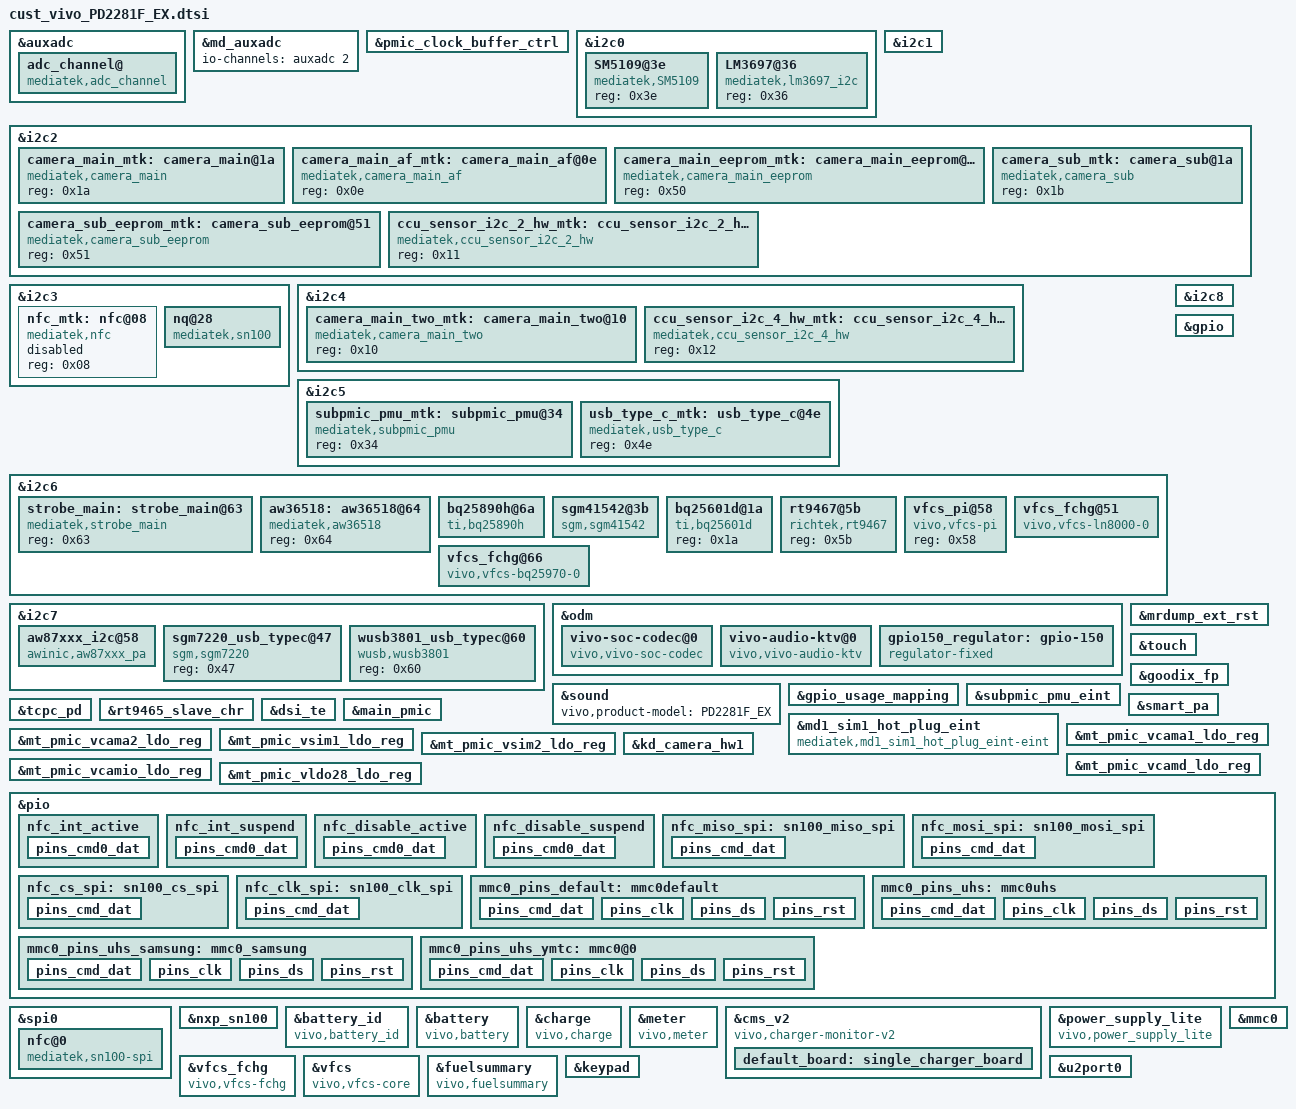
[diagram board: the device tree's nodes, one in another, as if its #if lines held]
/*
 * Generated by MTK SP DrvGen Version: 3.5.160809 for MT6768.
 * 2022-04-25 19:38:39
 * Do Not Modify The File.
 * Copyright Mediatek Inc. (c) 2016.
*/

/*************************
 * ADC DTSI File
*************************/

&auxadc {
	adc_channel@ {
		compatible = "mediatek,adc_channel";
		mediatek,temperature0 = <0>;
		mediatek,temperature1 = <1>;
		mediatek,adc_fdd_rf_params_dynamic_custom_ch = <2>;
		status = "okay";
	};
};
&md_auxadc {
	io-channels = <&auxadc 2>;
};


/*************************
 * CLK_BUF DTSI File
*************************/

&pmic_clock_buffer_ctrl {
	mediatek,clkbuf-quantity = <7>;
	mediatek,clkbuf-config = <2 1 2 2 0 0 0>;
	mediatek,clkbuf-driving-current = <1 1 1 1 1 1 1>;
	status = "okay";
};


/*************************
 * I2C DTSI File
*************************/

&i2c0 {
	#address-cells = <1>;
	#size-cells = <0>;
	clock-frequency = <400000>;
	mediatek,use-open-drain;

	SM5109@3e {
		compatible = "mediatek,SM5109";
		reg = <0x3e>;
		status = "okay";
	};

	LM3697@36 {
		compatible = "mediatek,lm3697_i2c";
		reg = <0x36>;
		status = "okay";
	};
};

&i2c1 {
	#address-cells = <1>;
	#size-cells = <0>;
	clock-frequency = <400000>;
	mediatek,use-open-drain;
};

&i2c2 {
	#address-cells = <1>;
	#size-cells = <0>;
	clock-frequency = <400000>;
	mediatek,use-open-drain;
	camera_main_mtk:camera_main@1a {
		compatible = "mediatek,camera_main";
		reg = <0x1a>;
		status = "okay";
	};
	camera_main_af_mtk:camera_main_af@0e {
		compatible = "mediatek,camera_main_af";
		reg = <0x0e>;
		status = "okay";
	};
	camera_main_eeprom_mtk:camera_main_eeprom@50 {
		compatible = "mediatek,camera_main_eeprom";
		reg = <0x50>;
		status = "okay";
	};
	camera_sub_mtk:camera_sub@1a {
		compatible = "mediatek,camera_sub";
		reg = <0x1b>;
		status = "okay";
	};
	camera_sub_eeprom_mtk:camera_sub_eeprom@51 {
		compatible = "mediatek,camera_sub_eeprom";
		reg = <0x51>;
		status = "okay";
	};

	ccu_sensor_i2c_2_hw_mtk:ccu_sensor_i2c_2_hw@11 {
		compatible = "mediatek,ccu_sensor_i2c_2_hw";
		reg = <0x11>;
		status = "okay";
	};

};

&i2c3 {
	#address-cells = <1>;
	#size-cells = <0>;
	clock-frequency = <400000>;
	mediatek,use-open-drain;
	nfc_mtk:nfc@08 {
		compatible = "mediatek,nfc";
		reg = <0x08>;
		status = "disable";
	};

};

&i2c4 {
	#address-cells = <1>;
	#size-cells = <0>;
	clock-frequency = <400000>;
	mediatek,use-open-drain;
	camera_main_two_mtk:camera_main_two@10 {
		compatible = "mediatek,camera_main_two";
		reg = <0x10>;
		status = "okay";
	};

	ccu_sensor_i2c_4_hw_mtk:ccu_sensor_i2c_4_hw@12 {
		compatible = "mediatek,ccu_sensor_i2c_4_hw";
		reg = <0x12>;
		status = "okay";
	};

};

&i2c5 {
	#address-cells = <1>;
	#size-cells = <0>;
	clock-frequency = <3400000>;
	mediatek,use-push-pull;
	subpmic_pmu_mtk:subpmic_pmu@34 {
		compatible = "mediatek,subpmic_pmu";
		reg = <0x34>;
		status = "okay";
	};

	usb_type_c_mtk:usb_type_c@4e {
		compatible = "mediatek,usb_type_c";
		reg = <0x4e>;
		status = "okay";
	};

};

&i2c6 {
	#address-cells = <1>;
	#size-cells = <0>;
	clock-frequency = <400000>;
	mediatek,use-open-drain;
    strobe_main: strobe_main@63 {   //添加I2C设备
        compatible = "mediatek,strobe_main";
        reg = <0x63>;
        status = "okay";
    };
    aw36518: aw36518@64 {   //添加I2C设备
        compatible = "mediatek,aw36518";
        reg = <0x64>;
        status = "okay";
    };
};

&i2c7 {
	#address-cells = <1>;
	#size-cells = <0>;
	clock-frequency = <400000>;
	mediatek,use-open-drain;
};

&i2c8 {
	#address-cells = <1>;
	#size-cells = <0>;
	clock-frequency = <400000>;
	mediatek,use-open-drain;
};

/* vivo audio dxl add start */
&odm {
	vivo-soc-codec@0 {
		compatible = "vivo,vivo-soc-codec";
		status = "okay";
	};

	vivo-audio-ktv@0 {
		compatible = "vivo,vivo-audio-ktv";
		status = "okay";
	};
};

&i2c7 {
	aw87xxx_i2c@58 {
		compatible = "awinic,aw87xxx_pa";
		reg = <0x58>;
		reset-gpio = <&pio 166 0>;
		vivo,aw87xxx-acf = "aw87xxx_acf_PD2281F_EX.bin";
		dev_index= <0>;
		status = "okay";
	};
};

&sound {
    vivo,product-model = "PD2281F_EX";
};

/* yanghen add for audio end */
/* Audio add for modify miso driving */
/* 4:4mA, 8:8mA, 12:12mA, 16:16mA */
/*
&mt6358_snd {
	mt6358-miso-driving = <4>;
};

&aud_dat_mosi_on {
	pins_cmd0_dat {
		drive-strength = <3>;
	};
	pins_cmd1_dat {
		drive-strength = <3>;
	};
	pins_cmd2_dat {
		drive-strength = <3>;
	};
	pins_cmd3_dat {
		drive-strength = <3>;
	};
};
*/
/* vivo audio dxl add End */

/*************************
 * GPIO DTSI File
*************************/

&gpio_usage_mapping {
	GPIO_SIM1_HOT_PLUG = <&pio 47 0>; //GPIO_SIM1_HOT_PLUG gpio46
	GPIO_SIM2_SIO = <&pio 155 0>;
	GPIO_SIM2_SRST = <&pio 156 0>;
	GPIO_SIM2_SCLK = <&pio 157 0>;
	GPIO_SIM1_SCLK = <&pio 172 0>;
	GPIO_SIM1_SRST = <&pio 173 0>;
	GPIO_SIM1_SIO = <&pio 174 0>;
	GPIO_FDD_BAND_SUPPORT_DETECT_1ST_PIN = <&pio 23 0>;
	GPIO_FDD_BAND_SUPPORT_DETECT_2ND_PIN = <&pio 21 0>;
	GPIO_FDD_BAND_SUPPORT_DETECT_3RD_PIN = <&pio 0 0>;
	GPIO_FDD_BAND_SUPPORT_DETECT_4TH_PIN = <&pio 5 0>;
	GPIO_FDD_BAND_SUPPORT_DETECT_5TH_PIN = <&pio 10 0>;
};

&gpio{
	gpio_init_default = <0 0 0 0 1 1 0>,
		<1 0 0 0 1 1 1>,
		<2 0 0 0 1 0 1>,
		<3 0 0 0 0 0 0>,//sub chg-int
		<4 0 0 0 0 0 0>,//MCQ857_COUT
		<5 0 0 0 1 1 0>,
		<6 0 0 0 1 0 0>,
		<7 0 0 0 1 1 1>, /* vivo audio modify for headset detect */
		<8 0 0 0 1 0 0>,
		<9 0 0 0 1 0 0>,
		<10 0 0 0 1 1 0>,
		<11 1 0 0 1 0 0>,
		<12 0 0 0 1 0 1>,
		<13 2 0 0 0 0 0>,
		<14 2 1 0 0 0 0>,
		<15 2 1 0 0 0 0>,
		<16 2 1 0 0 0 0>,
		<17 0 0 0 1 0 1>,
		<18 0 0 0 1 1 1>,
		<19 0 0 0 1 1 1>,
		<20 0 0 0 1 1 1>,
		<21 0 0 0 1 1 0>,
		<22 0 1 0 0 0 1>,//ZC_LDO_EN   MCU PI 3.3V
		<23 0 0 0 1 1 0>,
		<24 0 0 0 1 1 0>,//cam0 dvdd_en
		<25 0 1 0 1 0 0>,
		<26 0 1 0 1 0 0>,
		<27 0 1 0 1 0 0>,
		<28 0 1 0 1 0 0>,
		<29 0 0 0 1 1 0>,
		<30 0 0 0 1 1 0>,
		<31 0 0 0 1 0 0>,
		<32 7 1 0 0 0 0>,
		<33 7 0 0 1 0 0>,
		<34 7 0 0 1 0 0>,
		<35 7 0 0 1 0 0>,
		<36 0 1 0 1 0 1>,
		<37 2 1 0 0 0 0>,
		<38 2 1 0 0 0 0>,
		<39 0 0 0 1 1 1>,
		<40 2 0 0 1 0 0>,
		<41 0 0 0 1 1 1>,//cc logic int-gpio
		<42 0 0 0 1 1 1>,
		<43 1 1 0 0 0 0>,
		<44 1 0 0 1 0 0>,
		<45 0 1 0 0 0 0>,
		<46 0 0 0 0 0 0>,
		<47 1 0 0 0 0 1>,
		<48 1 0 0 1 1 1>,
		<49 1 0 0 1 1 1>,
		<50 1 0 0 1 1 1>,
		<51 1 0 0 1 1 1>,
		<52 0 0 0 1 1 0>,
		<53 1 0 0 1 0 0>,
		<54 1 0 0 1 0 0>,
		<55 0 0 0 1 1 0>,
		<56 0 0 0 1 1 0>,
		<57 1 0 0 1 0 0>,
		<58 0 0 0 1 0 0>,
		<59 1 0 0 1 0 0>,
		<60 1 0 0 1 0 0>,
		<61 1 0 0 1 0 0>,
		<62 1 0 0 1 0 0>,
		<63 1 0 0 1 0 0>,
		<64 1 0 0 1 0 0>,
		<65 1 0 0 1 0 0>,
		<66 1 0 0 1 0 0>,
		<67 1 0 0 1 0 0>,
		<68 1 0 0 1 0 0>,
		<69 0 0 0 1 1 0>,
		<70 1 0 0 1 0 0>,
		<71 1 0 0 1 0 0>,
		<72 1 0 0 1 0 0>,
		<73 1 0 0 1 0 0>,
		<74 1 0 0 1 0 0>,
		<75 1 0 0 1 0 0>,
		<76 1 0 0 1 0 0>,
		<77 1 0 0 1 0 0>,
		<78 0 0 0 1 1 0>,
		<79 0 0 0 1 1 0>,
		<80 0 0 0 1 0 0>,
		<81 2 0 0 1 1 1>,
		<82 1 0 0 1 1 1>,
		<83 1 0 0 1 1 1>,
		<84 2 0 0 1 1 1>,
		<85 2 0 0 1 0 0>,
		<86 2 1 0 0 0 0>,
		<87 2 1 0 0 0 0>,
		<88 2 1 0 0 0 0>,
		<89 1 0 0 1 1 1>,//flash i2c6 scl rear
		<90 1 0 0 1 1 1>,//flash i2c6 sda rear
		<91 0 0 0 1 1 0>,
		<92 0 1 0 1 1 1>,//CAM_FLASH_TORCH
		<93 1 0 0 1 1 0>,
		<94 0 1 0 0 0 0>,
		<95 1 0 0 1 1 0>,
		<96 1 1 0 0 0 0>,
		<97 0 1 0 0 0 0>,
		<98 0 1 0 0 0 0>,
		<99 1 1 0 0 0 0>,
		<100 1 0 0 1 0 1>,//cam0 mclk1
		<101 0 1 0 0 0 0>,
		<102 0 1 0 1 1 1>,//cam0 rst
		<103 1 0 0 0 0 1>,//cam0,1 i2c2 scl
		<104 1 0 0 0 0 1>,//cam0,1 i2c2 sda
		<105 1 0 0 0 0 1>,//cam2 i2c4 scl
		<106 1 0 0 0 0 1>,//cam2 i2c4 sda
		<107 0 1 0 0 0 0>,
		<108 1 0 0 1 0 1>,//cam1 mclk2
		<109 0 1 0 1 1 1>,//cam1 rst
		<110 0 1 0 0 0 0>,
		<111 0 0 0 0 0 1>,//MCU_INT_AP  PI_INT_AP
		<112 0 1 0 1 1 1>,//cam2 rst
		<113 0 0 0 1 0 0>,
		<114 0 0 0 1 0 0>,
		<115 0 0 0 1 0 0>,
		<116 0 0 0 1 0 0>,
		<117 0 0 0 1 0 0>,
		<118 0 0 0 1 0 0>,
		<119 0 0 0 1 0 0>,
		<120 0 0 0 1 0 0>,
		<121 0 0 0 1 0 0>,
		<134 1 0 0 1 0 1>,
		<135 1 1 0 0 0 0>,
		<136 1 1 0 0 0 0>,
		<137 1 1 0 0 0 0>,
		<138 1 1 0 0 0 0>,
		<139 1 1 0 0 0 0>,
		<140 1 0 0 1 0 0>,
		<141 1 0 0 1 0 0>,
		<142 1 0 0 1 0 0>,
		<143 1 0 0 1 0 0>,
		<144 1 0 0 1 0 0>,
		<145 1 1 0 0 0 0>,
		<146 1 1 0 0 0 0>,
		<147 1 1 0 0 0 0>,
		<148 1 1 0 0 0 0>,
		<149 1 1 0 0 0 0>,
		<150 0 1 0 1 1 1>,//cam0,1,2 avdd_en
		<151 0 1 0 0 0 0>,//usb oe
		<152 0 1 0 0 0 0>,//GPIO_FLASH_EN
		<153 0 1 0 0 0 0>,//GPIO_FLASH_STROBE
		<154 1 1 0 0 0 0>,
		<155 1 0 0 1 1 0>,
		<156 1 1 0 0 0 0>,
		<157 1 1 0 0 0 0>,
		<158 0 1 1 0 0 0>,//BATID_CTRL
		<159 0 1 0 0 0 1>,//usb sel
		<160 0 0 0 1 1 0>,
		<161 1 0 0 1 1 1>,
		<162 1 0 0 1 1 1>,
		<163 1 0 0 1 1 1>,
		<164 1 0 0 1 1 1>,
		<165 0 1 0 0 0 0>,
		<166 0 1 0 0 0 0>, /* audio PA rst, gpio mode, output-low, no-pull */
		<167 1 0 0 1 0 0>,
		<168 1 0 0 1 0 0>,
		<169 0 1 0 0 0 0>,
		<170 1 0 0 1 1 1>,
		<171 1 1 0 0 0 1>,
		<172 1 1 0 0 0 0>,
		<173 1 1 0 0 0 0>,
		<174 1 0 0 1 1 0>,
		<175 1 0 0 1 1 1>, /* audio I2C7, i2c mode, internal pull-up */
		<176 1 0 0 1 1 1>, /* audio I2C7, i2c mode, internal pull-up */
		<178 0 1 0 0 0 0>,
		<179 0 1 0 0 0 0>,
		<180 0 0 0 1 0 0>,
		<181 0 0 0 1 0 0>,
		<182 0 0 0 1 0 0>,
		<183 0 0 0 1 0 0>,
		<184 0 0 0 1 0 0>,
		<185 0 0 0 1 0 0>,
		<186 0 0 0 1 0 0>;
};


/*************************
 * EINT DTSI File
*************************/

#include <dt-bindings/interrupt-controller/irq.h>
#include <dt-bindings/interrupt-controller/arm-gic.h>

&mrdump_ext_rst {
	interrupt-parent = <&pio>;
	interrupts = <0 IRQ_TYPE_LEVEL_LOW 0 0>;
	deb-gpios = <&pio 0 0>;
	debounce = <512000>;
	status = "okay";
};

&touch {
	interrupt-parent = <&pio>;
	interrupts = <1 IRQ_TYPE_EDGE_FALLING 1 0>;
	status = "okay";
};

&goodix_fp {
	interrupt-parent = <&pio>;
	interrupts = <9 IRQ_TYPE_EDGE_RISING 9 0>;
	status = "okay";
};

&subpmic_pmu_eint {
	interrupt-parent = <&pio>;
	interrupts = <20 IRQ_TYPE_EDGE_FALLING 20 0>;
	status = "okay";
};

&smart_pa {
	interrupt-parent = <&pio>;
	interrupts = <39 IRQ_TYPE_LEVEL_LOW 39 0>;
	status = "okay";
};

&tcpc_pd {
	interrupt-parent = <&pio>;
	interrupts = <41 IRQ_TYPE_EDGE_FALLING 41 0>;
	status = "okay";
};

&rt9465_slave_chr {
	interrupt-parent = <&pio>;
	interrupts = <42 IRQ_TYPE_EDGE_FALLING 42 0>;
	status = "okay";
};

&dsi_te {
	interrupt-parent = <&pio>;
	interrupts = <44 IRQ_TYPE_EDGE_RISING 44 1>;
	status = "okay";
};

&main_pmic {
	interrupt-parent = <&pio>;
	interrupts = <144 IRQ_TYPE_LEVEL_HIGH 180 0>;
	status = "okay";
};



/*************************
 * MD1_EINT DTSI File
*************************/

&md1_sim1_hot_plug_eint {
	compatible = "mediatek,md1_sim1_hot_plug_eint-eint";
	interrupts = <0 8>;
	debounce = <0 100000>;
	dedicated = <0 0>;
	src_pin = <0 1>;
	sockettype = <0 0>;
	status = "okay";
};




/*************************
 * PMIC DTSI File
*************************/

&mt_pmic_vcama1_ldo_reg {
	regulator-name = "vcama1";
	regulator-default-on = <1>; /* 0:skip, 1: off, 2:on */
	status = "okay";
};
&mt_pmic_vcama2_ldo_reg {
	regulator-name = "vcama2";
	regulator-default-on = <1>; /* 0:skip, 1: off, 2:on */
	status = "okay";
};
&mt_pmic_vsim1_ldo_reg {
	regulator-name = "vsim1";
	regulator-default-on = <1>; /* 0:skip, 1: off, 2:on */
	status = "okay";
};
&mt_pmic_vsim2_ldo_reg {
	regulator-name = "vsim2";
	regulator-default-on = <1>; /* 0:skip, 1: off, 2:on */
	status = "okay";
};
&mt_pmic_vcamd_ldo_reg {
	regulator-name = "vcamd";
	regulator-default-on = <1>; /* 0:skip, 1: off, 2:on */
	status = "okay";
};
&mt_pmic_vcamio_ldo_reg {
	regulator-name = "vcamio";
	regulator-default-on = <1>; /* 0:skip, 1: off, 2:on */
	status = "okay";
};
&mt_pmic_vldo28_ldo_reg {
	regulator-name = "vldo28";
	regulator-default-on = <1>; /* 0:skip, 1: off, 2:on */
	status = "okay";
};

&kd_camera_hw1 {
	cam0_vcamio-supply = <&mt_pmic_vcamio_ldo_reg>;/*6358vcamio*/
	cam1_vcamio-supply = <&mt_pmic_vcamio_ldo_reg>;
	cam2_vcamio-supply = <&mt_pmic_vcamio_ldo_reg>;

	cam0_vcama-supply = <&gpio150_regulator>;/*AVDD 6769*/
	cam1_vcama-supply = <&gpio150_regulator>;
	cam2_vcama-supply = <&gpio150_regulator>;

	cam0_vcamd-supply = <&mt_pmic_vcamd_ldo_reg>;/*6358 DVDD*/
	cam1_vcamd-supply = <&mt_pmic_vcamd_ldo_reg>;/*6358 DVDD*/
	cam0_vcamaf_def-supply = <&mt_pmic_vldo28_ldo_reg>; //vcamaf_def

	cam0_enable_sensor = "s5kjnssq33pd2281f_mipi_raw s5kjnssq33v1pd2281f_mipi_raw";
	cam1_enable_sensor = "imx355pd2281f_mipi_raw s5k4h7pd2281f_mipi_raw";
	cam2_enable_sensor = "gc02m1bpd2281f_mipi_mono";
	status = "okay";
};

&odm {
	gpio150_regulator:gpio-150 {
			compatible = "regulator-fixed";
			regulator-name = "gpio150_regulator";
			gpio = <&pio 150 0x0>;
			enable-active-high;
			status = "okay";
	};
};

&camera_main_af_mtk {
	//vcamaf-supply = <&mt_pmic_vldo28_ldo_reg>;
};

/* NFC GPIO standardization begin*/
&pio {
	nfc_int_active: nfc_int_active {
		pins_cmd0_dat {
			pinmux = <PINMUX_GPIO9__FUNC_GPIO9>;
			bias-pull-up;
		};
	};
	nfc_int_suspend: nfc_int_suspend {
		pins_cmd0_dat {
			pinmux = <PINMUX_GPIO9__FUNC_GPIO9>;
			bias-pull-up;
		};
	};
	nfc_disable_active: nfc_disable_active {
		pins_cmd0_dat {
			pinmux = <PINMUX_GPIO54__FUNC_GPIO54>;
			bias-pull-up;
		};
		//pins_cmd1_dat {
			//pinmux = <PINMUX_GPIO17__FUNC_GPIO17>;
			//bias-pull-up;
		//};
	};
	nfc_disable_suspend: nfc_disable_suspend {
		pins_cmd0_dat {
			pinmux = <PINMUX_GPIO54__FUNC_GPIO54>;
			bias-disable;
		};
		//pins_cmd1_dat {
			//pinmux = <PINMUX_GPIO17__FUNC_GPIO17>;
			//bias-disable;
		//};
	};

};

&i2c3 {
	status = "okay";
	#address-cells = <1>;
	#size-cells = <0>;
	clock-frequency = <400000>;
	mediatek,use-open-drain;
	nq@28 {
		compatible = "mediatek,sn100";
		reg = <0x28>;
		vivo,nfc_support = <1>;
		vivo,boardversion_shift = <6>;
		vivo,boardversion_shift_2 = <7>;
		vivo,boardversion_mask = <1>;
		vivo,boardversion_num = <1>;
		vivo,boardversions = "0";
		vivo,nfc_chip_type = "PN560";
		vivo,project-name = "PD2281F_EX";
		mediatek,nq-irq = <&pio 9 0x00>;
		mediatek,nq-ven = <&pio 54 0x00>;
		//mediatek,nq-firm = <&pio 17 0x00>;
		//mediatek,nq-clkreq = <&pio 81 0x00>;
		interrupt-parent = <&pio>;
		interrupts = <9 0>;
		interrupt-names = "nfc_irq";
		pinctrl-names = "nfc_active", "nfc_suspend";
		pinctrl-0 = <&nfc_int_active &nfc_disable_active>;
		pinctrl-1 = <&nfc_int_suspend &nfc_disable_suspend>;
	};
};
/* NFC GPIO standardization end*/
/* NFC SPI standardization begin*/
&spi0 {
	#address-cells = <1>;
	#size-cells = <0>;
	nfc@0 {
		compatible = "mediatek,sn100-spi";
		reg = <0>;
		spi-max-frequency = <10000000>;
		status = "ok";
	};
};

&nxp_sn100 {
    status = "okay";
	pinctrl-names = "miso_spi","mosi_spi","cs_spi","clk_spi";
	pinctrl-0 = <&nfc_miso_spi>;
	pinctrl-1 = <&nfc_mosi_spi>;
	pinctrl-2 = <&nfc_cs_spi>;
	pinctrl-3 = <&nfc_clk_spi>;

};

&pio {
	nfc_miso_spi: sn100_miso_spi {
		pins_cmd_dat {
			pinmux = <PINMUX_GPIO32__FUNC_SPI0_MI>;
			drive-strength = <4>;
		};
	};
	nfc_mosi_spi: sn100_mosi_spi {
		pins_cmd_dat {
			pinmux = <PINMUX_GPIO34__FUNC_SPI0_MO>;
			drive-strength = <2>;
		};
	};
	nfc_cs_spi: sn100_cs_spi {
		pins_cmd_dat {
			pinmux = <PINMUX_GPIO33__FUNC_SPI0_CSB>;
			drive-strength = <4>;
			//bias-pull-up;
		};
	};
	nfc_clk_spi: sn100_clk_spi {
		pins_cmd_dat {
			pinmux = <PINMUX_GPIO35__FUNC_SPI0_CLK>;
			drive-strength = <1>;
		};
	};
};
/* NFC SPI standardization end*/

/*************************
 * POWER DTSI File
*************************/

/* fuxi add for battery&charge start */
#ifdef CONFIG_VIVO_CHARGING_NEW_ARCH
&battery_id {
	status = "okay";
	compatible = "vivo,battery_id";

	vivo,bat-adc-ctrl-gpio = <&pio 158 0>;

	io-channels = <&auxadc 2>;
	io-channel-names = "battery_id_adc";

	vivo,bat-name = "B-S2 ATL 5000","B-S1 LW 5000","B-S2 ATL 5000","B-S3 ATL 5000","UNKOWN","UNKOWN";
};

&battery {
	status = "okay";
	compatible = "vivo,battery";

	io-channels = <&auxadc 0>,
		<&auxadc 1>,
		<&auxadc 0>,
		<&auxadc 4>,
		<&auxadc 3>;
	io-channel-names = "primary_board_therm",
		"4g_pa_therm",
		"parallel_board_therm",
		"charge_ic_therm",
		"usb_conn_therm";
	vivo,vbat_from_fchg;

	vivo,low-volt-threshold = <3400>;
	vivo,soft-rise-percent = <96>;
	vivo,soft-rise-cumulative = <3>;
	vivo,soft-rise-keep-cumulative = <10>;
	vivo,percnet-sync-delta = <8>;
	vivo,percnet-sync-cumulative = <9>;
	vivo,full-sync-cumulative = <3>;
	vivo,soft-term-percent = <99>;
	vivo,soft-term-cumulative = <30>;
};

&charge {
	status = "okay";
	compatible = "vivo,charge";

	vivo,chg-wdt-s = <40>;
	vivo,re-chg-voltage-mv = <100>;
	vivo,prechg-voltage-mv = <3000>;
	vivo,iprechg-current-ma = <300>;
	vivo,iterm-current-ma = <245>;
	vivo,vreg-voltage-mv = <4430>;
	vivo,vindpm-voltage-mv = <4600>;
	vivo,sys-voltage-min-mv= <3300>;
	vivo,boostv-voltage-mv = <5150>;
	vivo,boostv-ilimit-ma = <1500>;
	vivo,ovp-voltage-mv = <15000>;

	/*
	 * 0  auto detect charging
	 * 1  vivo-normal chargine
	 * 2  vivo-single engine charging
	 * 3  vivo-dual engine charging
	 * 4  vivo-flash charging
	 */
	vivo,charge-scheme = <0>;
	vivo,direct-charger-enable;

	/*
	 * SUPPORTED_ADAPTER_DEFAULT = 0,
	 * SUPPORTED_ADAPTER_VIVO_LV_DCHG_5V_4500MA = 1,
	 * SUPPORTED_ADAPTER_VIVO_HV_DCHG_10V_2250MA = 2,
	 * SUPPORTED_ADAPTER_QC20__9V_2000MA = 3,
	 * SUPPORTED_ADAPTER_VIVO_HV_DCHG_10V_4000MA = 4,
	 * SUPPORTED_ADAPTER_MAX,
	 */
	vivo,supported-adapter = <4>;

	//parameter for 9V2A
	vivo,primary-ichg-max-ma = <2130>;
	vivo,parallel-ichg-max-ma = <1560>;

	vivo,flashchg-spec-ma = <2000 3300 8000>;
	vivo,fastchg-spec-ma = <2000 2100 3800>;
	vivo,normalchg-spec-ma = <2000 1500 2300>;

	/* 0---PMIC; 1---CHGIC */
	vivo,vbus-detect-source = <0>;

	//vivo,usboe-gpio = <&pio 151 0>;
	//vivo,usbsel-gpio = <&pio 159 0>;

	/*ffc*/
	//vivo,ffc-enable;
	vivo,ffc-iterm-ma = <(-750)>;
	vivo,ffc-vreg-mv = <4500>;
	vivo,ffc-temperature-range = <150 450>;
	vivo,ffc-full-vbat-table-size = <3>;
	vivo,ffc-full-vbat-table = <4498 4500 4490>;
	vivo,ffc-full-ibat-table-size = <3>;
	vivo,ffc-full-ibat-table = <150 199 (-854)>,
		<200 349 (-1122)>,
		<350 449 (-1268)>;

	/*otg reverse chg*/
	//vivo,otg-reverse-chg-support;
	vivo,otg-reverse-i-table-size = <5>;
	vivo,otg-reverse-i-table = <471 8888 800 1000>,
		<441 470 1200 1400>,
		<411 440 1600 1800>,
		<0 410 1800 2000>,
		<(-8888) 0 900 1100>;
};

&meter {
	status = "okay";
	compatible = "vivo,meter";

	vivo,load-capacity-delta-max = <60>;
	vivo,poweron-delta-capacity = <20>;
	vivo,poweron-low-capacity = <3>;
	vivo,volt-car-delta = <10>;
	vivo,car-volt-delta = <8>;
	vivo,meter-res-compesate = <10>;
	vivo,ocv-board-compesate = <0>;
	vivo,shipmode-cap-limit = <40>;
	vivo,shipmode-vol-limit = <4000>;

	/* 0---AGING_UNSUPPORTED; 1---DRIVER_SUPPORTED; 2---USPACE_SUPPORTED */
	vivo,battery-aging-support = <2>;

	vivo,capacity-mAh = <4900>;
	/*COLD_CHG COLD_DISCHG NORMAL_CHG NORMAL_DISCHG*/
	vivo,car-tune-value = <1050 1000 1050 1000>,
		<1050 1000 1070 1000>,
		<1050 1000 1010 1000>,
		<1050 1000 1010 1000>,
		<1050 1000 1010 1000>,
		<1050 1000 1010 1000>;

	vivo,bats-qmax = <3500 3950 4650 4920 4900>,
		<3950 4400 4550 4850 4800>,
		<4020 4320 4450 4750 4720>,
		<4020 4320 4450 4750 4720>,
		<4020 4320 4450 4750 4720>,
		<4020 4320 4450 4750 4720>;

	/* car-tune adjust remap */
	vivo,car-tune-adjust-enable;
	vivo,car-tune-adjust-size = <3>;
	vivo,car-tune-adjust-table = <0 10 (330) 6>,
		<11 20 (-30) 7>,
		<21 100 (-30) 8>;

	#include "bat_setting/PD2281F_EX_battery_table.dtsi"
};

&cms_v2 {
	compatible = "vivo,charger-monitor-v2";
	status = "okay";

	default_board: single_charger_board {
		       /*default board: keep in xxxxxx*/
		       support-board-version = "xxxxxx";

		       vivo,bat-det-method = <0>;//r:0, rc:1, eprom:2, ex-fg:3
		       vivo,bat-id-gpio = <&pio 158 0>;

		       /*
			  CHG0__CHARGING_TECHNOLOGY_NONE = 0,
			  CHG1__NORMAL_CHARGING,			//5V/2A normal charging
			  CHG2__QC2_CHARGING,				//9V/2A	QC2.0 charging
			  CHG3__LOW_VOLTAGE_DIRECT_CHARGING,		//5V/4.5A direct charging
			  CHG4__SINGLE_IC_DIV2_CHARGING,		//single IC Div/2 charging
			  CHG5__DUAL_IC_DIV2_CHARGING,			//Dual IC Div/2 charging
			  CHG6__DUAL_IC_DUAL_BATTERY_DIV2_CHARGING,	//Dual IC Div/2 charging
			  CHGX__CHARGING_TECHNOLOGY_MAX,
			*/
		       vivo,charging-technology = <4>;

		       //vivo,no-bat-warning;
		       //vivo,no-chg-timeout;
		       vivo,chg-timeout-mins = <900>;

		       //high temperature charger current control enable
		       vivo,htccc-enable;
		       vivo,htccc-data = <46 55 4100000 100000>;

		       //vivo,fbon-scale-enable;/*disable default*/
		       vivo,fbon-scale-data = <2 100 100>;

		       //vivo,switch-scale-enable;/*disable from rom4.0*/
		       vivo,switch-scale-data = <75 53>;

		       vivo,calling-scale-enable;
		       vivo,calling-scale-data = <100 21>;/*ibat:3900 * 0.54 = 2106,more than 1500,not exit dchg*/
		       vivo,calling-dchg-disable;

		       vivo,weixin-calling-scale-enable;
		       vivo,weixin-calling-scale-data = <100 104>;/*5000mA*/

		       //vivo,fixed-scale-enable;
		       vivo,fixed-scale-data = <120 3800 0>;/*dchg fixed time adjust the max ibat,disable default*/

		       /*data processing : batt-temp*/
		       vivo,dp-batt-temp-enable;
		       vivo,dp-batt-temp-data = <100>;

		       //vivo,vbat-r-comp = <17>;
		       vivo,vbat-r-comp = <0>;//use fchg vbat is battery cell voltage

		       /* charging current for devices in exhibition mode */
		       vivo,exhibition-mode-current-primary = <2048>;
		       vivo,exhibition-mode-current-parallel = <0>;

		       /*default tc parameter*/
		       //single charger ibat scale base on temperature battery cell info:1C/1.2C 3960mah
		       /* tmin, tmax, data, volt1, data_ex1, volt2, data_ex2. */
		       vivo,normal-tc-row-col = <8 11>;
		       vivo,normal-tc-data = <541 8888 0 0 0 0 0 0 0 0 0>,
			       <450 540 60 0 0 0 0 0 0 0 0>,
			       <200 449 256 4220000 222 4250000 178 0 0 0 0>,
			       <150 199 182 4250000 134 0 0 0 0 0 0>,
			       <100 149 151 4250000 121 0 0 0 0 0 0>,
			       <50 99 100 0 0 0 0 0 0 0 0>,
			       <20 49 100 0 0 0 0 0 0 0 0>,
			       <(-8888) (19) 0 0 0 0 0 0 0 0 0>;

		       /*flash tc parameter*/
		       vivo,flash-normal-tc-row-col = <9 11>;
		       vivo,flash-normal-tc-data = <550 8888 0 0 0 0 0 0 0 0 0>,
			       <450 549 60 0 0 0 0 0 0 0 0>,
			       <350 449 155 4100000 100 4300000 80 4460000 60 0 0>,
			       <200 349 155 4100000 100 4300000 80 4460000 60 0 0>,
			       <150 199 155 4100000 100 4250000 70 4460000 30 0 0>,
			       <100 149 100 0 0 0 0 0 0 0 0>,
			       <0 99 50 0 0 0 0 0 0 0 0>,
			       <(-100) (-1) 20 0 0 0 0 0 0 0 0>,
			       <(-8888) (-101) 0 0 0 0 0 0 0 0 0>;

		       /*adjust fastchg base on board temperature and fb off*/
		       vivo,intell-charge-enable;
		       vivo,parallel-temp-enable = <1 1>;//<x y> x:fb-on y:fb-off

		       /* Flash charge fb-on intell param */
		       vivo,primary-fbon-tc-row-col = <7 3>;
		       vivo,primary-fbon-tc-data = <466 8888 1600>,
			       <456 465 2200>,
			       <436 455 2500>,
			       <411 435 3600>,
			       <381 410 5000>,
			       <361 380 5700>,
			       <(-8888) 360 7600>;

		       vivo,parallel-fbon-tc-row-col = <1 3>;
		       vivo,parallel-fbon-tc-data = <(-8888) 8888 0>;

		       /* Flash charge fb-off intell param */
		       vivo,primary-fboff-tc-row-col = <8 3>;
		       vivo,primary-fboff-tc-data = <451 8888 1600>,
			       <436 450 2500>,
			       <421 435 3000>,
			       <391 420 4000>,
			       <376 390 4300>,
			       <366 375 5150>,
			       <356 365 6000>,
			       <(-8888) 355 7600>;
		       vivo,parallel-fboff-tc-row-col = <1 3>;
		       vivo,parallel-fboff-tc-data = <(-8888) 8888 0>;

		       /* 9v Fast charge fb-on intell param */
		       vivo,9v-primary-fbon-tc-row-col = <8 3>;
		       vivo,9v-primary-fbon-tc-data = <501 8888 100>,
			       <491 500 500>,
			       <476 490 700>,
			       <456 475 800>,
			       <431 455 900>,
			       <411 430 1000>,
			       <361 410 1000>,
			       <(-8888) 360 2000>;
		       vivo,9v-parallel-fbon-tc-row-col = <8 3>;
		       vivo,9v-parallel-fbon-tc-data = <501 8888 200>,
			       <491 500 300>,
			       <476 490 600>,
			       <456 475 700>,
			       <431 455 900>,
			       <411 430 1000>,
			       <361 410 1200>,
			       <(-8888) 360 1700>;
		       // second parallel parameter, for rt9467
		       vivo,9v-2nd-parallel-fbon-tc-row-col = <6 3>;
		       vivo,9v-2nd-parallel-fbon-tc-data = <450 8888 500>,
			       <430 449 800>,
			       <440 429 1000>,
			       <390 399 1100>,
			       <370 389 1300>,
			       <(-8888) 369 1500>;


		       /* 9v Fast charge fb-off intell param */
		       vivo,9v-primary-fboff-tc-row-col = <9 3>;
		       vivo,9v-primary-fboff-tc-data = <471 8888 500>,
			       <451 470 900>,
			       <431 450 1000>,
			       <401 430 1000>,
			       <386 400 1150>,
			       <371 385 1400>,
			       <351 370 1500>,
			       <341 350 1600>,
			       <(-8888) 340 2000>;
		       vivo,9v-parallel-fboff-tc-row-col = <9 3>;
		       vivo,9v-parallel-fboff-tc-data = <471 8888 300>,
			       <451 470 800>,
			       <431 450 900>,
			       <401 430 1150>,
			       <386 400 1150>,
			       <371 385 1200>,
			       <351 370 1400>,
			       <341 350 1600>,
			       <(-8888) 340 1600>;
		       // second parallel parameter, for rt9467
		       vivo,9v-2nd-parallel-fboff-tc-row-col = <7 3>;
		       vivo,9v-2nd-parallel-fboff-tc-data = <430 8888 500>,
			       <405 429 1200>,
			       <390 404 1300>,
			       <380 389 1500>,
			       <370 379 1550>,
			       <360 369 1700>,
			       <(-8888) 359 1800>;


		       /* 5v Normal charge fb-on intell param */
		       vivo,5v-primary-fbon-tc-row-col = <5 3>;
		       vivo,5v-primary-fbon-tc-data = <451 8888 500>,
			       <421 450 700>,
			       <401 420 1000>,
			       <381 400 1600>,
			       <(-8888) 380 2000>;
		       vivo,5v-parallel-fbon-tc-row-col = <1 3>;
		       vivo,5v-parallel-fbon-tc-data = <(-8888) 8888 0>;

		       /* 5v Normal charge fb-off intell param */
		       vivo,5v-primary-fboff-tc-row-col = <5 3>;
		       vivo,5v-primary-fboff-tc-data = <451 8888 700>,
			       <436 450 1000>,
			       <421 435 1200>,
			       <411 420 1500>,
			       <(-8888) 410 2000>;
		       vivo,5v-parallel-fboff-tc-row-col = <1 3>;
		       vivo,5v-parallel-fboff-tc-data = <(-8888) 8888 0>;

		       // Direct charging param
		       vivo,direct-charger-enable;//porting_check
		       vivo,ex-bms-psy-name = "bq_bms";

		       // bat_baord, usb_conn, pcb_conn(master_bat_conn), bat_conn
		       vivo,dchg-ntc-protect-enable;
		       vivo,dchg-ntc-protect-data = <750 800 850 850>;

		       vivo,adapter-cooldown-data = <900 850 3400>;
		       /*adapter power derate*/
		       vivo,adapter-power-derate-enable;

		       /* usb connecter protect param
			* USB_PROTECT_NONE = 0,
			* USB_CONN_TEMP_HEAT_PROTECT = BIT(0),
			* USB_ID_PROTECT = BIT(1),
			*/
		       vivo,usb-connecter-protect-enable = <1>;
		       vivo,usb-id-protect-data= <1100 1547 500>;/* 500K, 2M, fcc */
		       vivo,usb-conn-heat-protect-data-row-col = <2 4>;
		       vivo,usb-conn-heat-protect-data= <260 8888 670 620>,
			       <(-8888) 259 570 520>;

		       /*
			* max vbus of adapter:11v, max ibus of adapter:5A
			* min voltage of battery for half chg:3500mV,max voltage of battery for half charge:4100mV,
			* 5V2A charge min current threshold: 1000mA,5V2A charge max current threshold:2100mA,
			* flash charge min current threshold:5000mA,flash charge max current threshold:11000mA
			*/

		       /*default parameter*/
		       vivo,charge-param-judge-threshold = <9 2 3500 4300 1000 2100 2100 4600>;
		       /* factory mode charging test param */
		       vivo,charge-test-param-row-col = <12 3>;
		       vivo,charge-test-param-data = <0 0 5500>, /* cable resistance, min value, max value */
			       <0 0 5500>, /* master ibus, min ibus, max ibus */
			       <0 0 5500>, /* slave ibus, min ibus, max ibus */
			       <1 20 40>, /* batt therm ntc, min value, max value */
			       <1 20 45>, /* board therm ntc, min value, max value */
			       <0 20 50>, /* sub charger ntc, min value, max value */
			       <0 20 45>, /* usb con ntc, min value, max value */
			       <0 20 45>, /* usb con 1 ntc, double usb NTC, min value, max value */
			       <0 20 45>, /* bat btb master ntc, min value, max value */
			       <0 20 50>, /* bat btb sub ntc, min value, max value */
			       <0 20 50>, /* bat board ntc, min value, max value */
			       <0 20 50>; /* wireless charge coil ntc, min value, max value */

		       /*flash parameter*/
		       //vivo,flash-charge-param-judge-threshold = <11 3 3500 4100 1000 2200 4000 8200>;
		       vivo,flash-charge-param-judge-threshold = <11 4 3500 4100 1000 2200 4500 8200>;
		       /* factory mode charging test param */
		       vivo,flash-charge-test-param-row-col = <12 3>;
		       vivo,flash-charge-test-param-data = <1 0 5500>, /* cable resistance, min value, max value */
			       <1 0 5500>, /* master ibus, min ibus, max ibus */
			       <0 0 5500>, /* slave ibus, min ibus, max ibus */
			       <1 20 40>, /* batt therm ntc, min value, max value */
			       <1 20 45>, /* board therm ntc, min value, max value */
			       <0 20 50>, /* sub charger ntc, min value, max value */
			       <1 20 45>, /* usb con ntc, min value, max value */
			       <0 20 45>, /* usb con 1 ntc, double usb NTC, min value, max value */
			       <1 20 45>, /* bat btb master ntc, min value, max value */
			       <0 20 50>, /* bat btb sub ntc, min value, max value */
			       <0 20 50>, /* bat board ntc, min value, max value */
			       <0 20 50>; /* wireless charge coil ntc, min value, max value */
			#include "bat_setting/PD2281F_EX_battery_chg_params.dtsi"
		};
};

&power_supply_lite {
	status = "okay";
	compatible = "vivo,power_supply_lite";
};

&vfcs_fchg {
	status = "okay";
	compatible = "vivo,vfcs-fchg";
	vivo,fchg-version = <1>;
	vivo,fchg-dev-num = <1>;
};

&vfcs {
	status = "okay";
	compatible = "vivo,vfcs-core";
	vivo,vfcs-version = <0x1>;

	/*distinguish_gpio:mcu&vfcs*/
	vivo,vfc-driver-enable;

	/*
	 * BAT_TYPE_UNKNOWN = 0,
	 * BAT_TYPE_SINGLE_CELL = 1,
	 * BAT_TYPE_DUAL_CELL = 2,
	 * BAT_TYPE_MAX = 3,
	 */
	vivo,bat-type = <1>;

	/*project fchg ic nums*/
	vivo,fchg-ic-num = <1>;

	/*
	 * fchg IC parallel operation default(0)
	 * 0: standalone
	 * 1: master-slave
	 */
	vivo,fchg-ic-parallel-op = <0>;

	/*
	 * switch two-ic work,ibus-thr-ma = <x>
	 * switch two-ic work and switch three-ic work,ibus-thr-ma = <x y>
	 * ...,ibus-thr-ma = <x y ...>
	 */
	vivo,fchg-ic-switch-ibus-thr-ma = <1250>;

	/*exit fchg ibat thr*/
	vivo,exit-fchg-ibat-thr-ma = <1000>;

	vivo,fchg-vbus-max-mv = <11000>;
	vivo,fchg-vfloat-max-mv = <4460>;
	vivo,fchg-curr-max-ma = <7700>;

	/*fchg-mode: div2->bypass mode thr*/
	vivo,fchg-mode-switch-curr-thr-ma = <5000>;

	/*ap vbat cv thr(min-normal-max)*/
	//vivo,ap-vbat-cv-thr-mv = <8600 9000 9100>;

	/*fchg ic voltage (or get from charger ic)*/
	//vivo,fchg-ic-vbat-cv-thr-mv = <9200>;

	/*vbat exception thr(low-high)*/
	//vivo,vbat-exception-thr-mv = <6800 9000>;

	/*ex chg ic vbat exception thr(low-high)*/
	//vivo,chg-ic-vbat-exception-thr-mv = <6800 9270>;

	/*fchg_mode:
	 * [normal] vbat scale factor: bypass-div2
	 * [max] vbat scale factor: bypass-div2
	 */
	vivo,fchg-vbat-scale-factor = <100 213>;
	vivo,fchg-vbat-scale-factor-max = <110 238>;

	/*baud rate adjust support*/
	//vivo,baud-rate-adjust-support;

	/*cancel sbu adc*/
	vivo,sbu-adc-cancel;

	/*ufcs mode: limit fchg max current (power limit 33w)*/
	vivo,ufcs-fchg-curr-max-ma = <6000>;

	//battery voltage Internal resistance compensate
	vivo,vbat-r-comp-mohm = <60>;

	//power-ldo-supply = <&mt6368_vtp>;
	//vivo,power-ldo-config = <3300000 3300000 30000>;/*min_uV, max_uV, I_load_uA(keep in NPM)*/
	vivo,power-gpio = <&pio 22 0>; //ok
	vivo,int-gpio = <&pio 111 0>; //ok
	//vivo,reset-gpio = <&pio 144 0>; //SHIFT_EN gpio ok
	vivo,usbsel-gpio = <&pio 159 0>; //ok

	vivo,pps-fchg-support;
	//vivo,ex-fg-psy-name = "bq_bms";

	vivo,fw-bin-name = "pi_convenientpower.bin",
		"pi_chipsea.bin",
		"pi_nation.bin";
	//vivo,fw-bin-version = <0x70>;

	/*
	 * CIDM_NOT_SUPPORT = 0,//not support cable id detect
	 * CIDM_QCOM_1875mV_100K__adc__18K_sub_id_GND = 1,//1875mV-pullup + 100k ---^adc---18k + sbu_id      [default]
	 * CIDM_QCOM_1875mV_100K__adc__0K_fsa4480_sub_id_GND = 2,//1875mV-pullup + 100k ---^adc---0k + fsa4480 + sbu_id
	 * CIDM_EX_ADC_DETECT = 3,//USE the FSA4480 ADC
	 *
	 * CIDM_MAX = 4,
	 */
	vivo,cable-id-detect-method = <0>;

	//io-channels = /*<&pmk8550_vadc PM8550_ADC5_GEN3_AMUX_THM5_100K_PU>,pm8550 gpio1*/
	//	/*<&pmk8550_vadc PM8550_ADC5_GEN3_GPIO1_100K_PU>,pm8550 gpio2*/
	//	<&pmk8550_vadc PM8550B_ADC5_GEN3_AMUX_THM4_USB_THERM_100K_PU>,
	//	<&pmk8550_vadc PM8550_ADC5_GEN3_AMUX_THM2_100K_PU>,
	//	<&pmk8550_vadc PM8550B_ADC5_GEN3_AMUX2_GPIO5_100K_PU>;

	//io-channel-names = /*"sbu1_cable_id_adc",*/
	//	/*"sbu2_cable_id_adc",*/
	//	"usb_con_adc",
	//	"usb_con_adc1",
	//	"bat_btb_temp";

	vivo,vbat-too-high-thr-mv = <4502>;
	vivo,chg-ic-vbat-too-high-thr-mv = <4502>;

	/* normal, Tbat_min Tbat_max Vbat_termination_mV Ibat_termination_mA */
	vivo,ffc-support;
	vivo,ffc-fchg-cv-row-col = <7 4>;
	vivo,ffc-fchg-cv-data = <(-8888) 0 4502 500>,//Normal case [No FFC case]
		<1   100 4502  500>,//Normal case [No FFC case]
		<101 200 4502  500>,
		<201 250 4502  500>,
		<251 350 4502  500>,
		<351 450 4502  500>,
		<451 8888 4502 500>;//Normal case [No FFC case]
	/* Tbat_min Tbat_max Vbat_termination_mV Ibat_termination_mA */
	vivo,ffc-cv-foolproof-row-col = <4 4>;
	vivo,ffc-cv-foolproof-data = <101 200 4473 550>,
		<201 250 4473 550>,
		<251 350 4473 550>,
		<351 450 4473 550>;

	/* battery aging data */
	//vivo,batt-aging-enable;
	vivo,batt-aging-stages = <6>;
	vivo,batt-aging-cycle-range = <200 300 500 800 1000>;

	/* stages-0, Tbat_min Tbat_max Vbat_termination_mV Ibat_termination_mA */
	vivo,aging-ffc-fchg-cv-row-col-0 = <7 4>;
	vivo,aging-ffc-fchg-cv-data-0 = <(-8888) 0 8920 123>,//Normal case [No FFC case]
		<1   100 8920 123>,//Normal case [No FFC case]
		<101 200 9040 909>,
		<201 250 9040 1007>,
		<251 350 9040 1473>,
		<351 450 9040 1842>,
		<451 8888 8920 123>;//Normal case [No FFC case]
	/* Tbat_min Tbat_max Vbat_termination_mV Ibat_termination_mA */
	vivo,aging-ffc-cv-foolproof-row-col-0 = <4 4>;
	vivo,aging-ffc-cv-foolproof-data-0 = <101 200 8960 750>,
		<201 250 8960 750>,
		<251 350 8960 750>,
		<351 450 8960 750>;
	/* stages-1, Tbat_min Tbat_max Vbat_termination_mV Ibat_termination_mA */
	vivo,aging-ffc-fchg-cv-row-col-1 = <7 4>;
	vivo,aging-ffc-fchg-cv-data-1 = <(-8888) 0 8880 123>,//Normal case [No FFC case]
		<1   100  8880 123>,//Normal case [No FFC case]
		<101 200 9030 909>,
		<201 250 9026 1007>,
		<251 350 9016 1473>,
		<351 450 9010 1842>,
		<451 8888 8880 123>;//Normal case [No FFC case]
	/* Tbat_min Tbat_max Vbat_termination_mV Ibat_termination_mA */
	vivo,aging-ffc-cv-foolproof-row-col-1 = <4 4>;
	vivo,aging-ffc-cv-foolproof-data-1 = <101 200 8950 750>,
		<201 250 8946 750>,
		<251 350 8936 750>,
		<351 450 8930 750>;
	/* stages-2, Tbat_min Tbat_max Vbat_termination_mV Ibat_termination_mA */
	vivo,aging-ffc-fchg-cv-row-col-2 = <7 4>;
	vivo,aging-ffc-fchg-cv-data-2 = <(-8888) 0 8840 123>,//Normal case [No FFC case]
		<1   100  8840 123>,//Normal case [No FFC case]
		<101 200 8980 909>,
		<201 250 8976 1007>,
		<251 350 8966 1473>,
		<351 450 8960 1842>,
		<451 8888 8840 123>;//Normal case [No FFC case]
	/* Tbat_min Tbat_max Vbat_termination_mV Ibat_termination_mA */
	vivo,aging-ffc-cv-foolproof-row-col-2 = <4 4>;
	vivo,aging-ffc-cv-foolproof-data-2 = <101 200 8900 750>,
		<201 250 8896 750>,
		<251 350 8886 750>,
		<351 450 8880 750>;
	/* stages-3, Tbat_min Tbat_max Vbat_termination_mV Ibat_termination_mA */
	vivo,aging-ffc-fchg-cv-row-col-3 = <7 4>;
	vivo,aging-ffc-fchg-cv-data-3 = <(-8888) 0 8800 123>,//Normal case [No FFC case]
		<1   100  8800 123>,//Normal case [No FFC case]
		<101 200 8930 909>,
		<201 250 8926 1007>,
		<251 350 8916 1473>,
		<351 450 8910 1842>,
		<451 8888 8800 123>;//Normal case [No FFC case]
	/* Tbat_min Tbat_max Vbat_termination_mV Ibat_termination_mA */
	vivo,aging-ffc-cv-foolproof-row-col-3 = <4 4>;
	vivo,aging-ffc-cv-foolproof-data-3 = <101 200 8850 750>,
		<201 250 8846 750>,
		<251 350 8836 750>,
		<351 450 8830 750>;
	/* stages-4, Tbat_min Tbat_max Vbat_termination_mV Ibat_termination_mA */
	vivo,aging-ffc-fchg-cv-row-col-4 = <7 4>;
	vivo,aging-ffc-fchg-cv-data-4 = <(-8888) 0 8800 123>,//Normal case [No FFC case]
		<1   100  8800 123>,//Normal case [No FFC case]
		<101 200 8930 909>,
		<201 250 8926 1007>,
		<251 350 8916 1473>,
		<351 450 8910 1842>,
		<451 8888 8800 123>;//Normal case [No FFC case]
	/* Tbat_min Tbat_max Vbat_termination_mV Ibat_termination_mA */
	vivo,aging-ffc-cv-foolproof-row-col-4 = <4 4>;
	vivo,aging-ffc-cv-foolproof-data-4 = <101 200 8850 750>,
		<201 250 8846 750>,
		<251 350 8836 750>,
		<351 450 8830 750>;
	/* stages-5, Tbat_min Tbat_max Vbat_termination_mV Ibat_termination_mA */
	vivo,aging-ffc-fchg-cv-row-col-5 = <7 4>;
	vivo,aging-ffc-fchg-cv-data-5 = <(-8888) 0 8700 123>,//Normal case [No FFC case]
		<1   100  8700 123>,//Normal case [No FFC case]
		<101 200 8830 909>,
		<201 250 8826 1007>,
		<251 350 8816 1473>,
		<351 450 8810 1842>,
		<451 8888 8700 123>;//Normal case [No FFC case]
	/* Tbat_min Tbat_max Vbat_termination_mV Ibat_termination_mA */
	vivo,aging-ffc-cv-foolproof-row-col-5 = <4 4>;
	vivo,aging-ffc-cv-foolproof-data-5 = <101 200 8750 750>,
		<201 250 8746 750>,
		<251 350 8736 750>,
		<351 450 8730 750>;
};

&fuelsummary {
	status = "okay";
	compatible = "vivo,fuelsummary";

	/************************************************************
	 *
	 *  0   vivo-fastchg
	 *  1   qcom-dualchg
	 *  2   mtk-dualchg
	 *  3   qcom-normchg
	 *  4   mtk-normchg
	 *
	 ***********************************************************/
	chg-scheme = <2>;
	fex-version = <3>;
	fbon-ibat = <(-900)>;
	fboff-ibat = <(-1000)>;

	/* 0---AGING_UNSUPPORTED; 1---DRIVER_SUPPORTED; 2---USPACE_SUPPORTED */
	vivo,battery-aging-support = <2>;

	vivo,tshell-enable;
	vivo,tshell-sub-thmal-cnt = <11>;
	vivo,tshell_name = "vir_tbat", "vir_tbat_hot", "vir_tbat_cool", "vir_shell_max", "vir_shell_tmax", "vir_shell_bmax";
	vivo,tshell-subset-thmal = "mtktsAP", "mtktsbtsmdpa", "mtktsch4", "tzd_baton", "mtktsch3", "0", "0", "0" , "0", "0", "0";
	vivo,tshell_ntc_name = "BOARD_THERM", "4GPA", "CHARGERIC", "SUB_BOARD", "USB_CON", "0", "0", "0", "0", "0", "0", "vir_tbat_choose", "vir_tbat";
	vivo,tshell_node_name = "thermistor-ch0", "thermistor-ch1", "thermistor-ch4", "BATT_THERM", "USB_CON_THERM", "0", "0", "0" , "0", "0", "0";
	vivo,tshell_ntc_reg_name = "MT6769_AUX_IN0_NTC", "MT6769_AUX_IN1_NTC", "MT6769_AUX_IN4_NTC", "MT6358_BATON", "MT6769_AUX_IN3_NTC", "0", "0", "0", "0", "0", "0";
	vivo,tshell_hw_net_name = "AUX_IN0_NTC", "AUX_IN1_NTC", "CHG_THERM", "BATT_THERM", "USB_CON_THERM", "0", "0", "0", "0", "0", "0";
	vivo,tshell-coef-cnt = <67>;
	vivo,tshell-scene-cnt = <1>;
	vivo,vir_tbat_en = <1>;
	vivo,tshell-coef-data =
		<0 1 0
		0 0 0 0 0 0
		0 0 0 0 0 0
		0 0 0 0 0 0
		0 0 0 0 0 0
		0 0 0 0 0 0
		0 0 0 0 0 0
		0 0 0 0 0 0
		0 0 0 0 0 0
		0 0 0 0 0 0
		0 0 0 0 0 0
		0 0 0 0 0 0
		0>,
		<1 1 0
		0 0 0 0 0 0
		0 0 0 0 0 0
		0 0 0 0 0 0
		0 0 0 0 0 0
		0 0 0 0 0 0
		0 0 0 0 0 0
		0 0 0 0 0 0
		0 0 0 0 0 0
		0 0 0 0 0 0
		0 0 0 0 0 0
		0 0 0 0 0 0
		0>,
		<2 1 0
		0 0 0 0 0 0
		0 0 0 0 0 0
		0 0 0 0 0 0
		0 0 0 0 0 0
		0 0 0 0 0 0
		0 0 0 0 0 0
		0 0 0 0 0 0
		0 0 0 0 0 0
		0 0 0 0 0 0
		0 0 0 0 0 0
		0 0 0 0 0 0
		0>,
		<3 1 0
		0 0 0 0 0 0
		0 0 0 0 0 0
		0 0 0 0 0 0
		0 0 0 0 0 0
		0 0 0 0 0 0
		0 0 0 0 0 0
		0 0 0 0 0 0
		0 0 0 0 0 0
		0 0 0 0 0 0
		0 0 0 0 0 0
		0 0 0 0 0 0
		0>,
		<4 1 0
		0 0 0 0 0 0
		0 0 0 0 0 0
		0 0 0 0 0 0
		0 0 0 0 0 0
		0 0 0 0 0 0
		0 0 0 0 0 0
		0 0 0 0 0 0
		0 0 0 0 0 0
		0 0 0 0 0 0
		0 0 0 0 0 0
		0 0 0 0 0 0
		0>,
		<5 1 0
		0 0 0 0 0 0
		0 0 0 0 0 0
		0 0 0 0 0 0
		0 0 0 0 0 0
		0 0 0 0 0 0
		0 0 0 0 0 0
		0 0 0 0 0 0
		0 0 0 0 0 0
		0 0 0 0 0 0
		0 0 0 0 0 0
		0 0 0 0 0 0
		0>;
};

&i2c6 {
	#address-cells = <1>;
	#size-cells = <0>;
	status = "okay";
	clock-frequency = <100000>;

	bq25890h@6a {
		compatible = "ti,bq25890h";
		reg = <0x6a>;

		vivo,int-gpio = <&pio 6 0>;
	};

	sgm41542@3b {
		compatible = "sgm,sgm41542";
		reg = <0x3b>;

		vivo,int-gpio = <&pio 6 0>;
	};

	bq25601d@1a {
		compatible = "ti,bq25601d";
		reg = <0x1a>;

		//vivo,int-gpio = <&pio 3 0>;
		//vivo,enable-gpio = <&pio 22 0>;
		//vivo,chg-version-gpio = <&pio 77 0>;
	};

	rt9467@5b {
		compatible = "richtek,rt9467";
		reg = <0x5b>;

		//vivo,int-gpio = <&pio 3 0>;
		//vivo,enable-gpio = <&pio 166 0>;
		//vivo,chg-version-gpio = <&pio 77 0>;
	};

	vfcs_pi@58 {
		compatible = "vivo,vfcs-pi";
		reg = <0x58>;

		/*
		  comment: dtsi definition replacement driver definition ID
		  comment out: used driver definition ID
		*/
		//vivo,vfcs-dev-id = <0>;
	};

	vfcs_fchg@51 {
		status = "okay";
		compatible = "vivo,vfcs-ln8000-0";/*primary ic*/
		reg = <0x51>;

		//pinctrl-names = "default";
		//pinctrl-0 = <&sm1396_s_en_gpio_default>;

		vivo,fchg-dev-id = <0>;
		//vivo,en-gpio = <&tlmm 70 0>;

		vivo,ibus-ocp-thr-ma = <4100>;
		//io-channels = <&pmk8550_vadc PM8550B_ADC5_GEN3_AMUX3_GPIO6>;
		//io-channel-names = "smb1396_insns_adc";
	};

	vfcs_fchg@66 {
		status = "okay";
		vivo,ibus-ocp-thr-ma = <4100>;
		compatible = "vivo,vfcs-bq25970-0";/*primary ic*/
		reg = <0x66>;
	};
};

&i2c7 {
	#address-cells = <1>;
	#size-cells = <0>;
	status = "okay";
	clock-frequency = <400000>;

	sgm7220_usb_typec@47 {
		compatible = "sgm,sgm7220";
		reg = <0x47>;
		status = "okay";
	};

	wusb3801_usb_typec@60 {
		compatible = "wusb,wusb3801";
		reg = <0x60>;
		status = "okay";
	};
};
#endif
/* fuxi add for battery&charge end */

/*************************
 * KPD DTSI File
*************************/

&keypad {
	mediatek,kpd-key-debounce = <1024>;
	mediatek,kpd-sw-pwrkey = <116>;
	mediatek,kpd-hw-pwrkey = <8>;
	mediatek,kpd-sw-rstkey  = <114>;
	mediatek,kpd-hw-rstkey = <17>;
	mediatek,kpd-use-extend-type = <0>;
	/*HW Keycode [0~71] -> Linux Keycode*/
	mediatek,kpd-hw-map-num = <72>;
	mediatek,kpd-hw-init-map = <115 0 0 0 0 0 0 0 0 0 0 0 0 0 0 0 0 0 0 0 0 0 0 0 0 0 0 0 0 0 0 0 0 0 0 0 0 0 0 0 0 0 0 0 0 0 0 0 0 0 0 0 0 0 0 0 0 0 0 0 0 0 0 0 0 0 0 0 0 0 0 0 >;
	mediatek,kpd-pwrkey-eint-gpio = <0>;
	mediatek,kpd-pwkey-gpio-din  = <0>;
	mediatek,kpd-hw-dl-key0 = <17>;
	mediatek,kpd-hw-dl-key1 = <0>;
	mediatek,kpd-hw-dl-key2 = <8>;
	mediatek,kpd-hw-recovery-key = <17>;
	mediatek,kpd-hw-factory-key = <0>;
	status = "okay";
};


&mmc0 {
	is_PD2281F_project;
	status = "okay";
	pinctrl-names = "default","state_uhs", "state_uhs_samsung", "state_uhs_ymtc";
	pinctrl-0 = <&mmc0_pins_default>;
	pinctrl-1 = <&mmc0_pins_uhs>;
	pinctrl-2 = <&mmc0_pins_uhs_samsung>;
	pinctrl-3 = <&mmc0_pins_uhs_ymtc>;
	bus-width = <8>;
	max-frequency = <200000000>;
	cap-mmc-highspeed;
	mmc-ddr-1_8v;
	mmc-hs200-1_8v;
	mmc-hs400-1_8v;
	no-sdio;
	no-sd;
	hs400-ds-delay = <0x12814>;
	mediatek,cqhci;
	vmmc-supply = <&mt_pmic_vemc_ldo_reg>;
	non-removable;
};

/* modify SoC mmc driver strength by chengwenxing start */
&pio {
	mmc0_pins_default: mmc0default {
		pins_cmd_dat {
			pinmux = <PINMUX_GPIO123__FUNC_MSDC0_DAT0>,
				 <PINMUX_GPIO128__FUNC_MSDC0_DAT1>,
				 <PINMUX_GPIO125__FUNC_MSDC0_DAT2>,
				 <PINMUX_GPIO132__FUNC_MSDC0_DAT3>,
				 <PINMUX_GPIO126__FUNC_MSDC0_DAT4>,
				 <PINMUX_GPIO129__FUNC_MSDC0_DAT5>,
				 <PINMUX_GPIO127__FUNC_MSDC0_DAT6>,
				 <PINMUX_GPIO130__FUNC_MSDC0_DAT7>,
				 <PINMUX_GPIO122__FUNC_MSDC0_CMD>;
			input-enable;
			drive-strength = <4>;
		};
		pins_clk {
			pinmux = <PINMUX_GPIO124__FUNC_MSDC0_CLK>;
			drive-strength = <4>;
		};
		pins_ds {
			pinmux = <PINMUX_GPIO131__FUNC_MSDC0_DSL>;
			drive-strength = <4>;
		};
		pins_rst {
			pinmux = <PINMUX_GPIO133__FUNC_MSDC0_RSTB>;
			drive-strength = <4>;
		};
	};
	mmc0_pins_uhs: mmc0uhs {
		pins_cmd_dat {
			pinmux = <PINMUX_GPIO123__FUNC_MSDC0_DAT0>,
				 <PINMUX_GPIO128__FUNC_MSDC0_DAT1>,
				 <PINMUX_GPIO125__FUNC_MSDC0_DAT2>,
				 <PINMUX_GPIO132__FUNC_MSDC0_DAT3>,
				 <PINMUX_GPIO126__FUNC_MSDC0_DAT4>,
				 <PINMUX_GPIO129__FUNC_MSDC0_DAT5>,
				 <PINMUX_GPIO127__FUNC_MSDC0_DAT6>,
				 <PINMUX_GPIO130__FUNC_MSDC0_DAT7>,
				 <PINMUX_GPIO122__FUNC_MSDC0_CMD>;
			input-enable;
			drive-strength = <4>;
		};
		pins_clk {
			pinmux = <PINMUX_GPIO124__FUNC_MSDC0_CLK>;
			drive-strength = <4>;
		};
		pins_ds {
			pinmux = <PINMUX_GPIO131__FUNC_MSDC0_DSL>;
			drive-strength = <4>;
		};
		pins_rst {
			pinmux = <PINMUX_GPIO133__FUNC_MSDC0_RSTB>;
			drive-strength = <4>;
		};
	};
	mmc0_pins_uhs_samsung: mmc0_samsung {
		pins_cmd_dat {
			pinmux = <PINMUX_GPIO123__FUNC_MSDC0_DAT0>,
				 <PINMUX_GPIO128__FUNC_MSDC0_DAT1>,
				 <PINMUX_GPIO125__FUNC_MSDC0_DAT2>,
				 <PINMUX_GPIO132__FUNC_MSDC0_DAT3>,
				 <PINMUX_GPIO126__FUNC_MSDC0_DAT4>,
				 <PINMUX_GPIO129__FUNC_MSDC0_DAT5>,
				 <PINMUX_GPIO127__FUNC_MSDC0_DAT6>,
				 <PINMUX_GPIO130__FUNC_MSDC0_DAT7>,
				 <PINMUX_GPIO122__FUNC_MSDC0_CMD>;
			input-enable;
			drive-strength = <2>;
		};
		pins_clk {
			pinmux = <PINMUX_GPIO124__FUNC_MSDC0_CLK>;
			drive-strength = <4>;
		};
		pins_ds {
			pinmux = <PINMUX_GPIO131__FUNC_MSDC0_DSL>;
			drive-strength = <4>;
		};
		pins_rst {
			pinmux = <PINMUX_GPIO133__FUNC_MSDC0_RSTB>;
			drive-strength = <4>;
		};
	};
	mmc0_pins_uhs_ymtc: mmc0@0 {
		pins_cmd_dat {
			pinmux = <PINMUX_GPIO123__FUNC_MSDC0_DAT0>,
				 <PINMUX_GPIO128__FUNC_MSDC0_DAT1>,
				 <PINMUX_GPIO125__FUNC_MSDC0_DAT2>,
				 <PINMUX_GPIO132__FUNC_MSDC0_DAT3>,
				 <PINMUX_GPIO126__FUNC_MSDC0_DAT4>,
				 <PINMUX_GPIO129__FUNC_MSDC0_DAT5>,
				 <PINMUX_GPIO127__FUNC_MSDC0_DAT6>,
				 <PINMUX_GPIO130__FUNC_MSDC0_DAT7>,
				 <PINMUX_GPIO122__FUNC_MSDC0_CMD>;
			input-enable;
			drive-strength = <3>;
		};
		pins_clk {
			pinmux = <PINMUX_GPIO124__FUNC_MSDC0_CLK>;
			drive-strength = <3>;
		};
		pins_ds {
			pinmux = <PINMUX_GPIO131__FUNC_MSDC0_DSL>;
			drive-strength = <4>;
		};
		pins_rst {
			pinmux = <PINMUX_GPIO133__FUNC_MSDC0_RSTB>;
			drive-strength = <4>;
		};
	};
};
/* PD2281F_EX modify SoC mmc driver strength by chengwenxing end */

//vivo USB add for usb eye begin
&u2port0{
    mediatek,eye-vrt = <2>; /* 0~7 */
    mediatek,eye-term = <3>; /* 0~7 */
    mediatek,eye-rev6 = <2>; /* 0~3 */
    mediatek,eye-disc = <0xf>; /* 0~8 */
    mediatek,eye-intr = <0x1e>; /* 0~0xlf */
    mediatek,host-eye-vrt = <3>; /* 0~7 */
    mediatek,host-eye-term = <4>; /* 0~7 */
    mediatek,host-eye-rev6 = <3>; /* 0~3 */
    mediatek,host-eye-disc = <0xc>; /* 0~8 */
    mediatek,host-eye-intr = <0x14>; /* 0~0xlf */
};
//vivo USB add for usb eye begin
